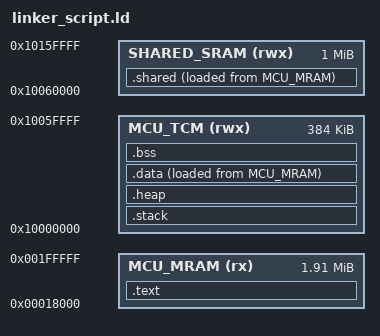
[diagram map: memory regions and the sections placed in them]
/******************************************************************************
 *
 * linker_script.ld - Linker script for applications using startup_gnu.c
 *
 *****************************************************************************/
ENTRY(Reset_Handler)

MEMORY
{
    MCU_MRAM     (rx)  : ORIGIN = 0x00018000, LENGTH = 1998848
    MCU_TCM      (rwx) : ORIGIN = 0x10000000, LENGTH = 393216
    SHARED_SRAM  (rwx) : ORIGIN = 0x10060000, LENGTH = 1048576
}

SECTIONS
{
    .text :
    {
        . = ALIGN(4);
        KEEP(*(.isr_vector))
        KEEP(*(.patch))
        *(.text)
        *(.text*)
        *(.rodata)
        *(.rodata*)
        . = ALIGN(4);
        _etext = .;
    } > MCU_MRAM

    /* User stack section initialized by startup code. */
    .stack (NOLOAD):
    {
        . = ALIGN(8);
        *(.stack)
        *(.stack*)
        . = ALIGN(8);
    } > MCU_TCM

    .heap (NOLOAD): {
        __heap_start__ = .;
        end = __heap_start__;
        _end = end;
        __end = end;
        KEEP(*(.heap))
        __heap_end__ = .;
        __HeapLimit = __heap_end__;
    } > MCU_TCM

    .data :
    {
        . = ALIGN(4);
        _sdata = .;
        *(.data)
        *(.data*)
        *(.ramfunc) 
        . = ALIGN(4);
        _edata = .;
    } > MCU_TCM AT>MCU_MRAM

    /* used by startup to initialize data */
    _init_data = LOADADDR(.data);

    .bss :
    {
        . = ALIGN(4);
        _sbss = .;
        *(.bss)
        *(.bss*)
        *(COMMON)
        . = ALIGN(4);
        _ebss = .;
    } > MCU_TCM

    .shared (NOLOAD):
    {
        . = ALIGN(4);
        KEEP(*(.resource_table))
        KEEP(*(.shared))
        . = ALIGN(4);
    } > SHARED_SRAM AT>MCU_MRAM
    .ARM.attributes 0 : { *(.ARM.attributes) }
}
